AUTOSAR XML (schema 3-1-5)
package /led_rte_system_mpc5516it/BlinkerKit
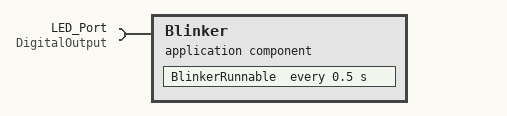
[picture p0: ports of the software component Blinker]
  application software component type Blinker
    require port LED_Port: required-interface=DigitalOutput
  internal behavior BlinkerBehavior: component=Blinker
    timing event Blinker_timingEvent: start-on-event=BlinkerRunnable, period=0.5
    runnable BlinkerRunnable: can-be-invoked-concurrently=true
      sync call syncCallPoint_1: operation=LED_Port.Set
  swc implementation BlinkerImplementation: behavior=BlinkerBehavior
